# HC32F448JCTI register map
File version: 1.0
CPU: CM4 r0p1, little endian, MPU, FPU, 4 interrupt priority bits
Registers are 32-bit, read-write, reset 0x0 unless marked. A register's access mark holds for its fields unless they carry their own. Offsets are from the block's base; [hi:lo] are bit positions; {n}, {i} and the like mark numbered series; 'fields as' and 'values as' point back to an identical list.

## EFM
Base 0x40010400
0x00 FAPRT
  [15:0] FAPRT
0x04 KEY1
0x08 KEY2
0x14 FSTP
  [0] FSTP
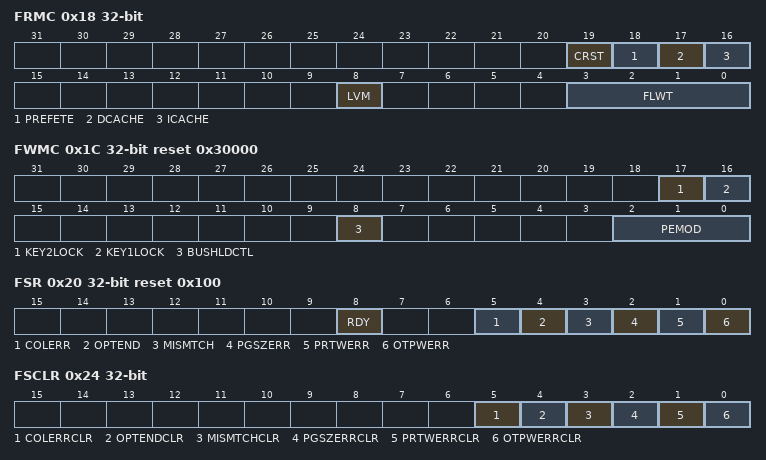
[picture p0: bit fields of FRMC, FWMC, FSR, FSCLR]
0x18 FRMC
  [19] CRST, [18] PREFETE, [17] DCACHE, [16] ICACHE, [8] LVM, [3:0] FLWT
0x1C FWMC reset 0x30000
  [17] KEY2LOCK, [16] KEY1LOCK, [8] BUSHLDCTL, [2:0] PEMOD
0x20 FSR ro reset 0x100
  [8] RDY, [5] COLERR, [4] OPTEND, [3] MISMTCH, [2] PGSZERR, [1] PRTWERR, [0] OTPWERR
0x24 FSCLR
  [5] COLERRCLR, [4] OPTENDCLR, [3] MISMTCHCLR, [2] PGSZERRCLR, [1] PRTWERRCLR, [0] OTPWERRCLR
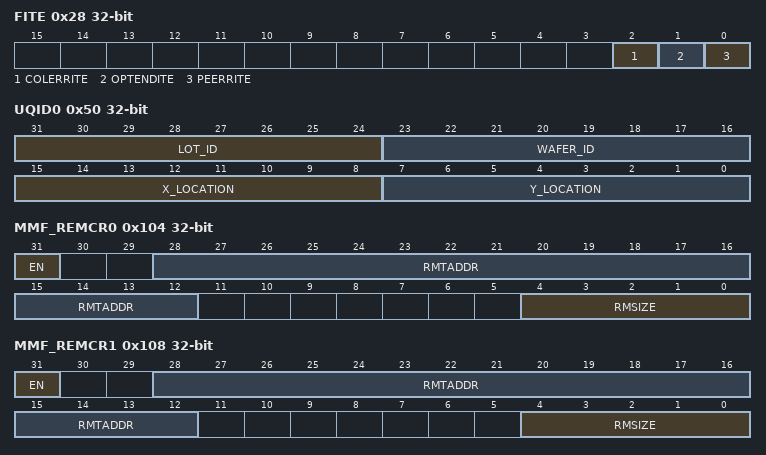
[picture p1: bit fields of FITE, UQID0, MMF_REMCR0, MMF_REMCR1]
0x28 FITE
  [2] COLERRITE, [1] OPTENDITE, [0] PEERRITE
0x2C FSWP ro
  [0] FSWP
0x40 CHIPID ro reset 0x58480448
0x50 UQID0 ro
  [31:24] LOT_ID, [23:16] WAFER_ID, [15:8] X_LOCATION, [7:0] Y_LOCATION
0x54 UQID1 ro
  [31:0] LOT_ID
0x58 UQID2 ro
  [7:0] LOT_ID
0x100 MMF_REMPRT
  [15:0] MMF_REMPRT
0x104 MMF_REMCR0
  [31] EN, [28:12] RMTADDR, [4:0] RMSIZE
0x108 MMF_REMCR1
  [31] EN, [28:12] RMTADDR, [4:0] RMSIZE
0x180 WLOCK
  [0] WLOCK0
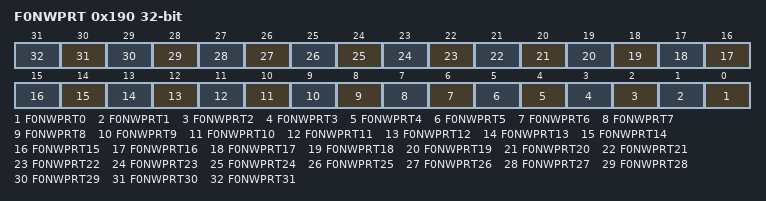
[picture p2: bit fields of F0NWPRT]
0x190 F0NWPRT
  [n] F0NWPRT{n} (n=0..31)

## EMB0
Base 0x40017C00
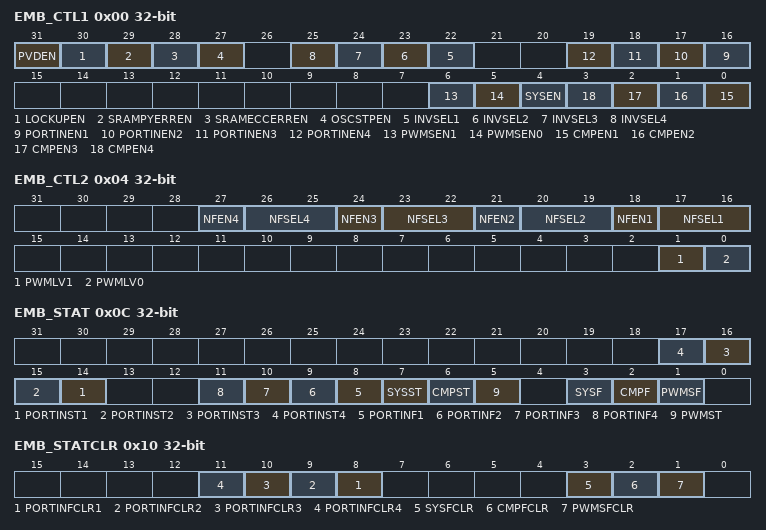
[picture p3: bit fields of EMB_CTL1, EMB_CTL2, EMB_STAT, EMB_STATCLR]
0x00 EMB_CTL1
  [31] PVDEN, [30] LOCKUPEN, [29] SRAMPYERREN, [28] SRAMECCERREN, [27] OSCSTPEN, [n+21] INVSEL{n} (n=1..4), [n+15] PORTINEN{n} (n=1..4), [6] PWMSEN1, [5] PWMSEN0, [4] SYSEN, [n-1] CMPEN{n} (n=1..4)
0x04 EMB_CTL2
  [3n+15] NFEN{n} (n=1..4), [3n+14:3n+13] NFSEL{n} (n=1..4), [1] PWMLV1, [0] PWMLV0
0x08 EMB_SOE
  [0] SOE
0x0C EMB_STAT ro
  [n+13] PORTINST{n} (n=1..4), [n+7] PORTINF{n} (n=1..4), [7] SYSST, [6] CMPST, [5] PWMST, [3] SYSF, [2] CMPF, [1] PWMSF
0x10 EMB_STATCLR wo
  [n+7] PORTINFCLR{n} (n=1..4), [3] SYSFCLR, [2] CMPFCLR, [1] PWMSFCLR
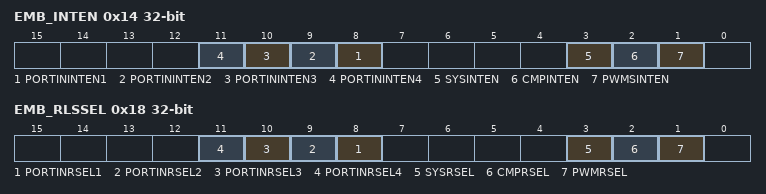
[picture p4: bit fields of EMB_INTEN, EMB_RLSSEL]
0x14 EMB_INTEN
  [n+7] PORTININTEN{n} (n=1..4), [3] SYSINTEN, [2] CMPINTEN, [1] PWMSINTEN
0x18 EMB_RLSSEL
  [n+7] PORTINRSEL{n} (n=1..4), [3] SYSRSEL, [2] CMPRSEL, [1] PWMRSEL

## EMB1 — desc EMB
Base 0x40017C20
Same registers: EMB2 0x40017C40, EMB3 0x40017C60
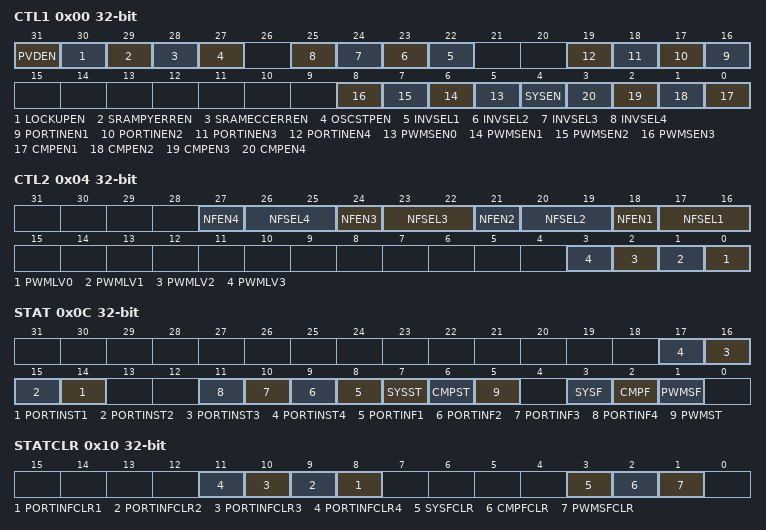
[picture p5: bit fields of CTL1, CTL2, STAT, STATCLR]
0x00 CTL1
  [31] PVDEN, [30] LOCKUPEN, [29] SRAMPYERREN, [28] SRAMECCERREN, [27] OSCSTPEN, [n+21] INVSEL{n} (n=1..4), [n+15] PORTINEN{n} (n=1..4), [n+5] PWMSEN{n} (n=0..3), [4] SYSEN, [n-1] CMPEN{n} (n=1..4)
0x04 CTL2
  [3n+15] NFEN{n} (n=1..4), [3n+14:3n+13] NFSEL{n} (n=1..4), [n] PWMLV{n} (n=0..3)
0x08 SOE
  [0] SOE
0x0C STAT ro
  [n+13] PORTINST{n} (n=1..4), [n+7] PORTINF{n} (n=1..4), [7] SYSST, [6] CMPST, [5] PWMST, [3] SYSF, [2] CMPF, [1] PWMSF
0x10 STATCLR wo
  [n+7] PORTINFCLR{n} (n=1..4), [3] SYSFCLR, [2] CMPFCLR, [1] PWMSFCLR
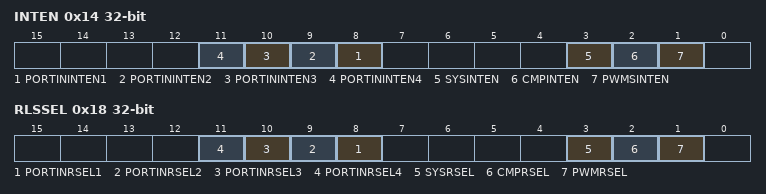
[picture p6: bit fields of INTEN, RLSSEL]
0x14 INTEN
  [n+7] PORTININTEN{n} (n=1..4), [3] SYSINTEN, [2] CMPINTEN, [1] PWMSINTEN
0x18 RLSSEL
  [n+7] PORTINRSEL{n} (n=1..4), [3] SYSRSEL, [2] CMPRSEL, [1] PWMRSEL

## FCM
Base 0x40048400
0x00 LVR
  [15:0] LVR
0x04 UVR
  [15:0] UVR
0x08 CNTR ro
  [15:0] CNTR
0x0C STR
  [0] START
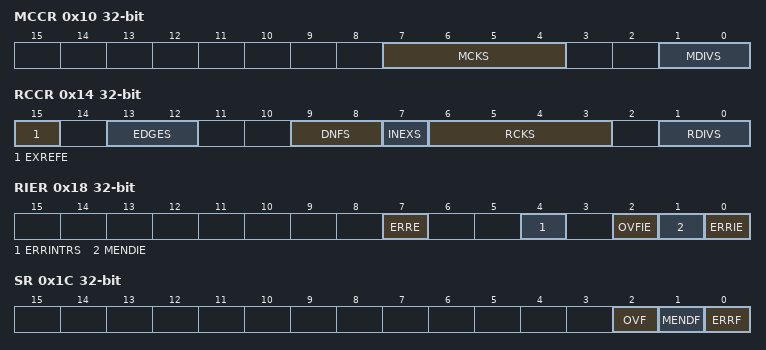
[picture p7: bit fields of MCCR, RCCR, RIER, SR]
0x10 MCCR
  [7:4] MCKS, [1:0] MDIVS
0x14 RCCR
  [15] EXREFE, [13:12] EDGES, [9:8] DNFS, [7] INEXS, [6:3] RCKS, [1:0] RDIVS
0x18 RIER
  [7] ERRE, [4] ERRINTRS, [2] OVFIE, [1] MENDIE, [0] ERRIE
0x1C SR ro
  [2] OVF, [1] MENDF, [0] ERRF
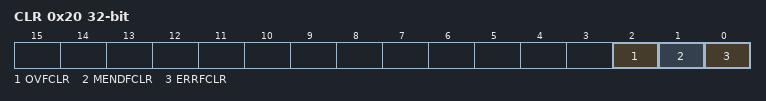
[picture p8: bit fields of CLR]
0x20 CLR wo
  [2] OVFCLR, [1] MENDFCLR, [0] ERRFCLR

## GPIO
Base 0x40053800
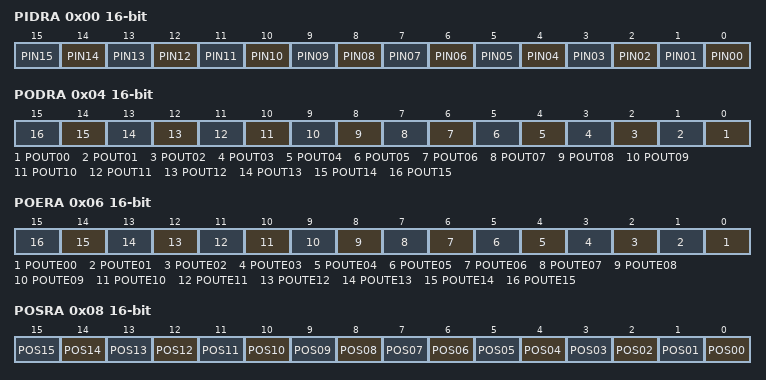
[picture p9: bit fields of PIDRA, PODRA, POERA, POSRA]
0x00 PIDRA 16-bit ro
  [n] PIN{n:02} (n=0..15)
0x04 PODRA 16-bit
  [n] POUT{n:02} (n=0..15)
0x06 POERA 16-bit
  [n] POUTE{n:02} (n=0..15)
0x08 POSRA 16-bit
  [n] POS{n:02} (n=0..15)
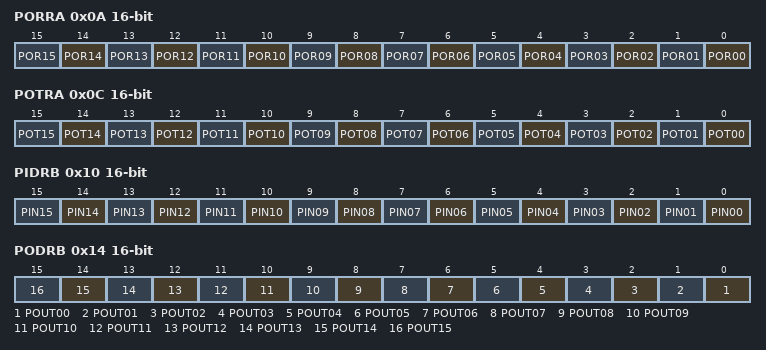
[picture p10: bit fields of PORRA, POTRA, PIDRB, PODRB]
0x0A PORRA 16-bit
  [n] POR{n:02} (n=0..15)
0x0C POTRA 16-bit
  [n] POT{n:02} (n=0..15)
0x10 PIDRB 16-bit ro
  [n] PIN{n:02} (n=0..15)
0x14 PODRB 16-bit
  [n] POUT{n:02} (n=0..15)
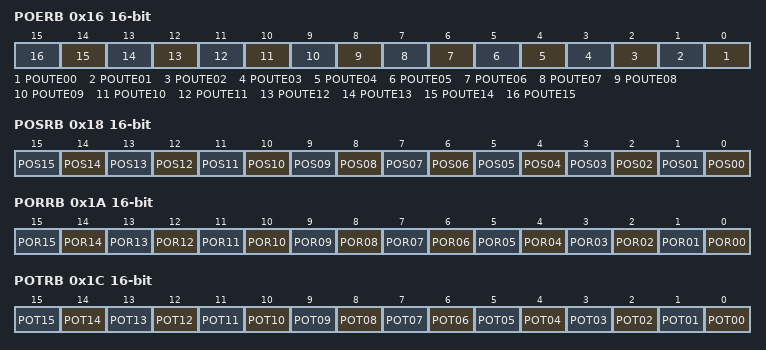
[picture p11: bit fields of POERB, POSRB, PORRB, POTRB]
0x16 POERB 16-bit
  [n] POUTE{n:02} (n=0..15)
0x18 POSRB 16-bit
  [n] POS{n:02} (n=0..15)
0x1A PORRB 16-bit
  [n] POR{n:02} (n=0..15)
0x1C POTRB 16-bit
  [n] POT{n:02} (n=0..15)
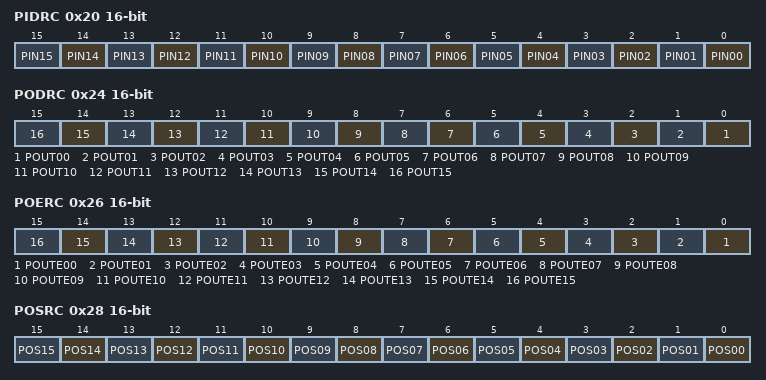
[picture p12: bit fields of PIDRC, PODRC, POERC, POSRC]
0x20 PIDRC 16-bit ro
  [n] PIN{n:02} (n=0..15)
0x24 PODRC 16-bit
  [n] POUT{n:02} (n=0..15)
0x26 POERC 16-bit
  [n] POUTE{n:02} (n=0..15)
0x28 POSRC 16-bit
  [n] POS{n:02} (n=0..15)
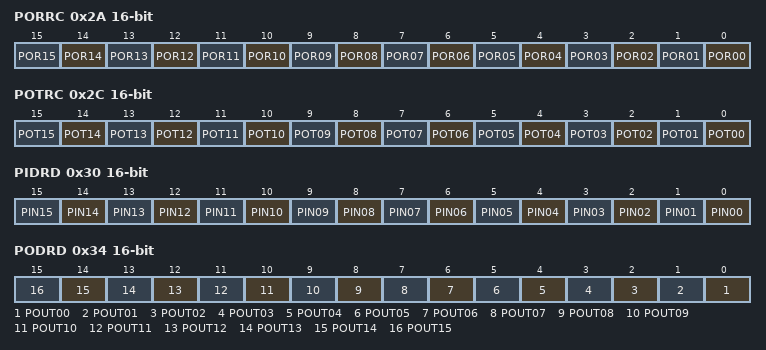
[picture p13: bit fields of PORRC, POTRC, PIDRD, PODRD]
0x2A PORRC 16-bit
  [n] POR{n:02} (n=0..15)
0x2C POTRC 16-bit
  [n] POT{n:02} (n=0..15)
0x30 PIDRD 16-bit ro
  [n] PIN{n:02} (n=0..15)
0x34 PODRD 16-bit
  [n] POUT{n:02} (n=0..15)
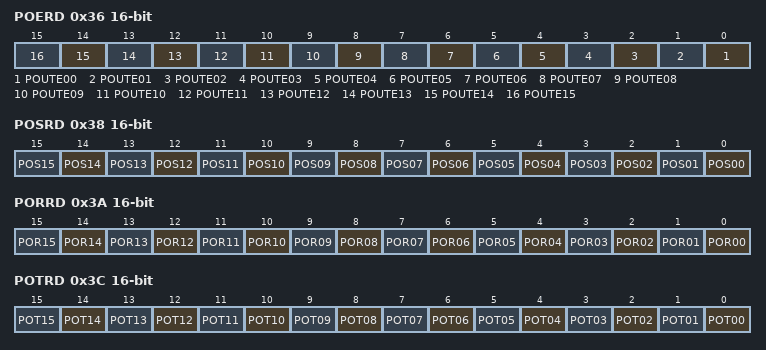
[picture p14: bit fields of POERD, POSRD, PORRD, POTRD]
0x36 POERD 16-bit
  [n] POUTE{n:02} (n=0..15)
0x38 POSRD 16-bit
  [n] POS{n:02} (n=0..15)
0x3A PORRD 16-bit
  [n] POR{n:02} (n=0..15)
0x3C POTRD 16-bit
  [n] POT{n:02} (n=0..15)
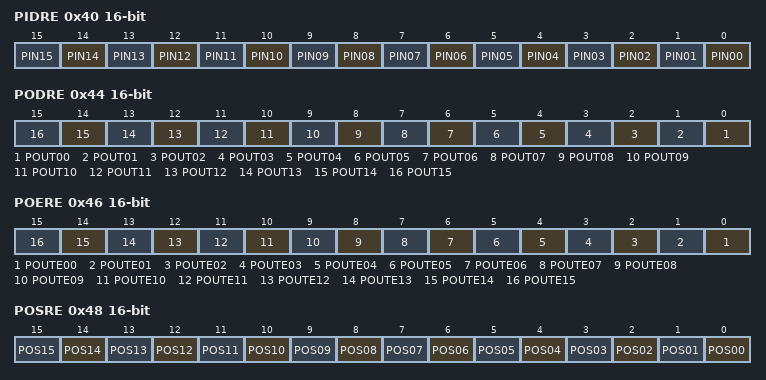
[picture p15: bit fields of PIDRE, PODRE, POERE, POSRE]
0x40 PIDRE 16-bit ro
  [n] PIN{n:02} (n=0..15)
0x44 PODRE 16-bit
  [n] POUT{n:02} (n=0..15)
0x46 POERE 16-bit
  [n] POUTE{n:02} (n=0..15)
0x48 POSRE 16-bit
  [n] POS{n:02} (n=0..15)
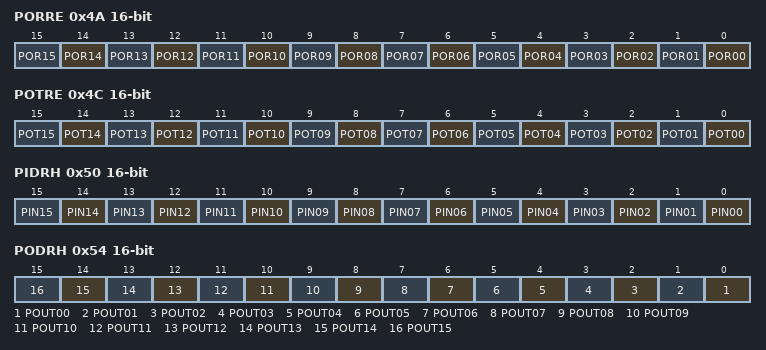
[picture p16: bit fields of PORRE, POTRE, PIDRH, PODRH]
0x4A PORRE 16-bit
  [n] POR{n:02} (n=0..15)
0x4C POTRE 16-bit
  [n] POT{n:02} (n=0..15)
0x50 PIDRH 16-bit ro
  [n] PIN{n:02} (n=0..15)
0x54 PODRH 16-bit
  [n] POUT{n:02} (n=0..15)
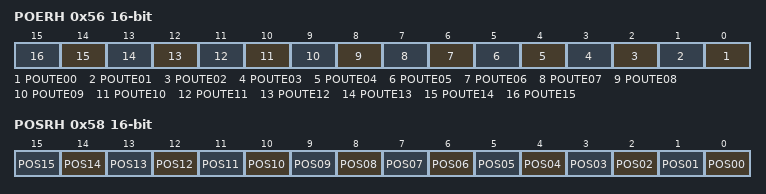
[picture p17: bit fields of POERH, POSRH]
0x56 POERH 16-bit
  [n] POUTE{n:02} (n=0..15)
0x58 POSRH 16-bit
  [n] POS{n:02} (n=0..15)
0x5A PORRH 16-bit
  [n] POR{n:02} (n=0..15)
0x5C POTRH 16-bit
  [n] POT{n:02} (n=0..15)
0x3F4 PSPCR 16-bit reset 0x1F
  [4:0] SPFE
0x3F8 PCCR 16-bit reset 0x1000
  [14:12] RDWT, [5:0] BFSEL
0x3FC PWPR 16-bit
  [15:8] WP wo, [0] WE
{0x400+4i} PCRA{i} 16-bit (i=0..15)
  [15] DDIS, [14] LTE, [13] PINAE, [12] INTE, [10] CINSEL, [9] INVE, [8] PIN ro, [7] PUD, [6] PUU, [5:4] DRV, [2] NOD, [1] POUTE, [0] POUT
{0x402+4i} PFSRA{i} 16-bit (i=0..15)
  [8] BFE, [5:0] FSEL
{0x440+4i} PCRB{i} 16-bit (i=0..15)
  fields as PCRA0
{0x442+4i} PFSRB{i} 16-bit (i=0..15)
  [8] BFE, [5:0] FSEL
{0x480+4i} PCRC{i} 16-bit (i=0..15)
  fields as PCRA0
{0x482+4i} PFSRC{i} 16-bit (i=0..15)
  [8] BFE, [5:0] FSEL
{0x4C0+4i} PCRD{i} 16-bit (i=0..2)
  fields as PCRA0
{0x4C2+4i} PFSRD{i} 16-bit (i=0..2)
  [8] BFE, [5:0] FSEL
{0x4C0+4i} PCRD{i} 16-bit (i=8..11)
  fields as PCRA0
{0x4C2+4i} PFSRD{i} 16-bit (i=8..11)
  [8] BFE, [5:0] FSEL
0x500 PCRE0 16-bit
  fields as PCRA0
0x502 PFSRE0 16-bit
  [8] BFE, [5:0] FSEL
0x504 PCRE1 16-bit reset 0x40
  fields as PCRA0
0x506 PFSRE1 16-bit reset 0xD
  [8] BFE, [5:0] FSEL
{0x500+4i} PCRE{i} 16-bit (i=2..4)
  fields as PCRA0
{0x502+4i} PFSRE{i} 16-bit (i=2..4)
  [8] BFE, [5:0] FSEL
{0x500+4i} PCRE{i} 16-bit (i=12..15)
  fields as PCRA0
{0x502+4i} PFSRE{i} 16-bit (i=12..15)
  [8] BFE, [5:0] FSEL
{0x540+4i} PCRH{i} 16-bit (i=0..2)
  fields as PCRA0
{0x542+4i} PFSRH{i} 16-bit (i=0..2)
  [8] BFE, [5:0] FSEL
